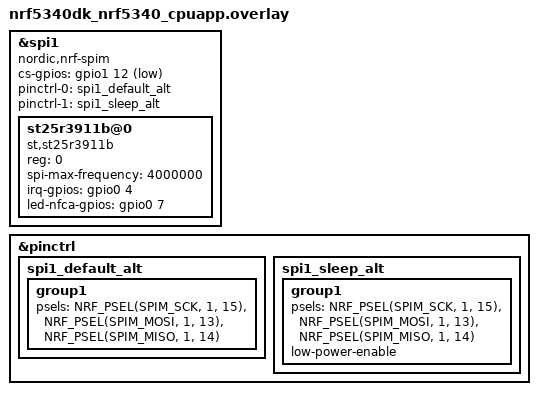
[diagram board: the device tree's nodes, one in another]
&spi1 {
	compatible = "nordic,nrf-spim";
	status = "okay";
	cs-gpios = <&gpio1 12 GPIO_ACTIVE_LOW>;

	pinctrl-0 = <&spi1_default_alt>;
	pinctrl-1 = <&spi1_sleep_alt>;
	pinctrl-names = "default", "sleep";
	st25r3911b@0 {
		compatible = "st,st25r3911b";
		reg = <0>;
		spi-max-frequency = <4000000>;
		irq-gpios = <&gpio0 4 GPIO_ACTIVE_HIGH>;
		led-nfca-gpios = <&gpio0 7 GPIO_ACTIVE_HIGH>;
	};
};

&pinctrl {
	spi1_default_alt: spi1_default_alt {
		group1 {
			psels = <NRF_PSEL(SPIM_SCK, 1, 15)>,
				<NRF_PSEL(SPIM_MOSI, 1, 13)>,
				<NRF_PSEL(SPIM_MISO, 1, 14)>;
		};
	};

	spi1_sleep_alt: spi1_sleep_alt {
		group1 {
			psels = <NRF_PSEL(SPIM_SCK, 1, 15)>,
				<NRF_PSEL(SPIM_MOSI, 1, 13)>,
				<NRF_PSEL(SPIM_MISO, 1, 14)>;
			low-power-enable;
		};
	};

};
